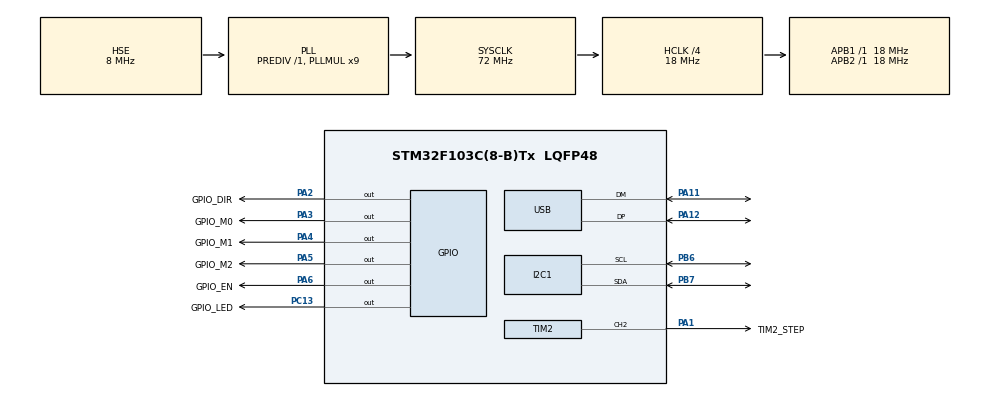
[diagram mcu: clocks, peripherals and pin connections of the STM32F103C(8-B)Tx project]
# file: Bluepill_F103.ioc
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Dma.I2C1_RX.0.Direction=DMA_PERIPH_TO_MEMORY
Dma.I2C1_RX.0.Instance=DMA1_Channel7
Dma.I2C1_RX.0.MemDataAlignment=DMA_MDATAALIGN_BYTE
Dma.I2C1_RX.0.MemInc=DMA_MINC_ENABLE
Dma.I2C1_RX.0.Mode=DMA_NORMAL
Dma.I2C1_RX.0.PeriphDataAlignment=DMA_PDATAALIGN_BYTE
Dma.I2C1_RX.0.PeriphInc=DMA_PINC_DISABLE
Dma.I2C1_RX.0.Priority=DMA_PRIORITY_HIGH
Dma.Request0=I2C1_RX
FREERTOS.Tasks01=defaultTask,24,128,StartDefaultTask,Default,NULL,Dynamic,NULL,NULL
FREERTOS.configTOTAL_HEAP_SIZE=10244
FREERTOS.configUSE_NEWLIB_REENTRANT=1
Mcu.Family=STM32F1
Mcu.Name=STM32F103C(8-B)Tx
Mcu.Package=LQFP48
NVIC.DMA1_Channel7_IRQn=true\:5\:0\:false\:false\:true\:true\:false\:true\:true
NVIC.I2C1_ER_IRQn=true\:5\:0\:false\:false\:true\:true\:true\:true\:true
NVIC.I2C1_EV_IRQn=true\:5\:0\:false\:false\:true\:true\:true\:true\:true
NVIC.PriorityGroup=NVIC_PRIORITYGROUP_4
NVIC.TIM2_IRQn=true\:5\:0\:false\:false\:true\:true\:true\:true\:true
NVIC.TIM3_IRQn=true\:15\:0\:false\:false\:true\:false\:false\:true\:true
NVIC.TimeBase=TIM3_IRQn
NVIC.TimeBaseIP=TIM3
NVIC.USB_HP_CAN1_TX_IRQn=true\:5\:0\:false\:false\:true\:true\:true\:true\:true
NVIC.USB_LP_CAN1_RX0_IRQn=true\:5\:0\:false\:false\:true\:true\:false\:true\:true
PA1.GPIO_Label=TIM2_STEP
PA1.Signal=S_TIM2_CH2
PA11.Mode=Device
PA11.Signal=USB_DM
PA12.Mode=Device
PA12.Signal=USB_DP
PA13.Mode=Serial_Wire
PA13.Signal=SYS_JTMS-SWDIO
PA14.Mode=Serial_Wire
PA14.Signal=SYS_JTCK-SWCLK
PA2.GPIO_Label=GPIO_DIR
PA2.Signal=GPIO_Output
PA3.GPIO_Label=GPIO_M0
PA3.Signal=GPIO_Output
PA4.GPIO_Label=GPIO_M1
PA4.Signal=GPIO_Output
PA5.GPIO_Label=GPIO_M2
PA5.Signal=GPIO_Output
PA6.GPIO_Label=GPIO_EN
PA6.Signal=GPIO_Output
PB6.Mode=I2C
PB6.Signal=I2C1_SCL
PB7.Mode=I2C
PB7.Signal=I2C1_SDA
PC13-TAMPER-RTC.GPIO_Label=GPIO_LED
PC13-TAMPER-RTC.Signal=GPIO_Output
PD0-OSC_IN.Mode=HSE-External-Oscillator
PD0-OSC_IN.Signal=RCC_OSC_IN
PD1-OSC_OUT.Mode=HSE-External-Oscillator
PD1-OSC_OUT.Signal=RCC_OSC_OUT
ProjectManager.HeapSize=0x200
ProjectManager.StackSize=0x400
ProjectManager.TargetToolchain=STM32CubeIDE
RCC.AHBCLKDivider=RCC_SYSCLK_DIV4
RCC.AHBFreq_Value=18000000
RCC.APB1Freq_Value=18000000
RCC.APB1TimFreq_Value=18000000
RCC.APB2Freq_Value=18000000
RCC.APB2TimFreq_Value=18000000
RCC.HCLKFreq_Value=18000000
RCC.PLLMUL=RCC_PLL_MUL9
RCC.SYSCLKFreq_VALUE=72000000
RCC.SYSCLKSource=RCC_SYSCLKSOURCE_PLLCLK
RCC.USBFreq_Value=48000000
RCC.USBPrescaler=RCC_USBCLKSOURCE_PLL_DIV1_5
SH.S_TIM2_CH2.0=TIM2_CH2,Output Compare2 CH2
TIM2.Channel-Output\ Compare2\ CH2=TIM_CHANNEL_2
TIM2.Prescaler=17
USB_DEVICE.CLASS_NAME_FS=CUSTOM_HID
USB_DEVICE.USBD_CUSTOMHID_OUTREPORT_BUF_SIZE=64
USB_DEVICE.USBD_CUSTOM_HID_REPORT_DESC_SIZE=36
USB_DEVICE.VirtualMode=CustomHid
USB_DEVICE.VirtualModeFS=Custom_Hid_FS
VP_FREERTOS_VS_CMSIS_V2.Mode=CMSIS_V2
VP_SYS_VS_tim3.Mode=TIM3
VP_TIM2_VS_ClockSourceINT.Mode=Internal
VP_USB_DEVICE_VS_USB_DEVICE_CUSTOM_HID_FS.Mode=CUSTOM_HID_FS
board=custom

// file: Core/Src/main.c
/* USER CODE BEGIN Header */
/**
  ******************************************************************************
  * @file           : main.c
  * @brief          : Main program body
  ******************************************************************************
  * @attention
  *
  * Copyright (c) 2026 STMicroelectronics.
  * All rights reserved.
  *
  * This software is licensed under terms that can be found in the LICENSE file
  * in the root directory of this software component.
  * If no LICENSE file comes with this software, it is provided AS-IS.
  *
  ******************************************************************************
  */
/* USER CODE END Header */
#include "main.h"
#include "dma.h"
#include "i2c.h"
#include "tim.h"
#include "usb_device.h"
#include "gpio.h"

void SystemClock_Config(void);

int main(void)
{

  /* MCU Configuration--------------------------------------------------------*/

  /* Reset of all peripherals, Initializes the Flash interface and the Systick. */
  HAL_Init();

  /* Configure the system clock */
  SystemClock_Config();

  /* Initialize all configured peripherals */
  MX_GPIO_Init();
  MX_DMA_Init();
  MX_I2C1_Init();
  MX_TIM2_Init();
  /* USER CODE BEGIN 2 */

  BaseType_t status;
  status = xTaskCreate(AppInit, "TaskCreate", 256, NULL, 10, NULL) ;
  if( status == pdFAIL){
	  Error_Handler();
  }

  vTaskStartScheduler();
  /* USER CODE END 2 */

  /* Infinite loop */
  while (1)
  {

  }
}

void SystemClock_Config(void)
{
  RCC_OscInitTypeDef RCC_OscInitStruct = {0};
  RCC_ClkInitTypeDef RCC_ClkInitStruct = {0};
  RCC_PeriphCLKInitTypeDef PeriphClkInit = {0};

  /** Initializes the RCC Oscillators according to the specified parameters
  * in the RCC_OscInitTypeDef structure.
  */
  RCC_OscInitStruct.OscillatorType = RCC_OSCILLATORTYPE_HSE;
  RCC_OscInitStruct.HSEState = RCC_HSE_ON;
  RCC_OscInitStruct.HSEPredivValue = RCC_HSE_PREDIV_DIV1;
  RCC_OscInitStruct.HSIState = RCC_HSI_ON;
  RCC_OscInitStruct.PLL.PLLState = RCC_PLL_ON;
  RCC_OscInitStruct.PLL.PLLSource = RCC_PLLSOURCE_HSE;
  RCC_OscInitStruct.PLL.PLLMUL = RCC_PLL_MUL9;
  if (HAL_RCC_OscConfig(&RCC_OscInitStruct) != HAL_OK)
  {
    Error_Handler();
  }

  /** Initializes the CPU, AHB and APB buses clocks
  */
  RCC_ClkInitStruct.ClockType = RCC_CLOCKTYPE_HCLK|RCC_CLOCKTYPE_SYSCLK
                              |RCC_CLOCKTYPE_PCLK1|RCC_CLOCKTYPE_PCLK2;
  RCC_ClkInitStruct.SYSCLKSource = RCC_SYSCLKSOURCE_PLLCLK;
  RCC_ClkInitStruct.AHBCLKDivider = RCC_SYSCLK_DIV4;
  RCC_ClkInitStruct.APB1CLKDivider = RCC_HCLK_DIV1;
  RCC_ClkInitStruct.APB2CLKDivider = RCC_HCLK_DIV1;

  if (HAL_RCC_ClockConfig(&RCC_ClkInitStruct, FLASH_LATENCY_2) != HAL_OK)
  {
    Error_Handler();
  }
  PeriphClkInit.PeriphClockSelection = RCC_PERIPHCLK_USB;
  PeriphClkInit.UsbClockSelection = RCC_USBCLKSOURCE_PLL_DIV1_5;
  if (HAL_RCCEx_PeriphCLKConfig(&PeriphClkInit) != HAL_OK)
  {
    Error_Handler();
  }
}

void HAL_TIM_PeriodElapsedCallback(TIM_HandleTypeDef *htim)
{
  if (htim->Instance == TIM3)
  {
    HAL_IncTick();
  }
}

void Error_Handler(void)
{
  __disable_irq();
  while (1)
  {
  }
}

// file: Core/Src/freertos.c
/* USER CODE BEGIN Header */
/**
  ******************************************************************************
  * File Name          : freertos.c
  * Description        : Code for freertos applications
  ******************************************************************************
  * @attention
  *
  * Copyright (c) 2026 STMicroelectronics.
  * All rights reserved.
  *
  * This software is licensed under terms that can be found in the LICENSE file
  * in the root directory of this software component.
  * If no LICENSE file comes with this software, it is provided AS-IS.
  *
  ******************************************************************************
  */
/* USER CODE END Header */

#include "FreeRTOS.h"
#include "task.h"
#include "main.h"
#include "cmsis_os.h"

/* Definitions for defaultTask */
osThreadId_t defaultTaskHandle;
const osThreadAttr_t defaultTask_attributes = {
  .name = "defaultTask",
  .stack_size = 128 * 4,
  .priority = (osPriority_t) osPriorityNormal,
};

void StartDefaultTask(void *argument);

extern void MX_USB_DEVICE_Init(void);
void MX_FREERTOS_Init(void); /* (MISRA C 2004 rule 8.1) */

void MX_FREERTOS_Init(void) {

  /* Create the thread(s) */
  /* creation of defaultTask */
  defaultTaskHandle = osThreadNew(StartDefaultTask, NULL, &defaultTask_attributes);

}

void StartDefaultTask(void *argument)
{
  /* init code for USB_DEVICE */
  MX_USB_DEVICE_Init();
  for(;;)
  {
    osDelay(1);
  }
}
